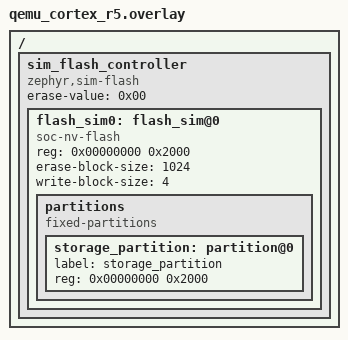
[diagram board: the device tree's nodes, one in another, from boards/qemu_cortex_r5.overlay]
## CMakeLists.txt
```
# Copyright (c) 2023 Intel Corporation.
# SPDX-License-Identifier: Apache-2.0

cmake_minimum_required(VERSION 3.20.0)
find_package(Zephyr REQUIRED HINTS $ENV{ZEPHYR_BASE})
project(llext_simple_test)

target_sources(app PRIVATE
  src/test_llext_simple.c
)

target_include_directories(app PRIVATE
  ${ZEPHYR_BASE}/include
  ${ZEPHYR_BASE}/kernel/include
  ${ZEPHYR_BASE}/arch/${ARCH}/include
)

set(ext_names
	hello_world
	logging
	relative_jump
	object
	syscalls
	threads_kernel_objects
	export_dependent
	export_dependency
)

if(CONFIG_ARM)
  if(NOT CONFIG_CPU_CORTEX_M0 AND NOT CONFIG_CPU_CORTEX_M0PLUS AND NOT CONFIG_CPU_CORTEX_M1)
    list(APPEND ext_names movwmovt)
  endif()
endif()

if (CONFIG_LLEXT_TYPE_ELF_RELOCATABLE AND NOT CONFIG_ARM)
    list(APPEND ext_names pre_located)
endif()

if (CONFIG_LLEXT_STORAGE_WRITABLE)
    list(APPEND ext_names find_section detached_fn)
endif()

if (NOT CONFIG_LLEXT_TYPE_ELF_SHAREDLIB)
    # ELF shared libraries do not support init sections
    list(APPEND ext_names init_fini)
endif()

# generate extension targets foreach extension given by 'ext_names'
foreach(ext_name ${ext_names})
  set(ext_src ${PROJECT_SOURCE_DIR}/src/${ext_name}_ext.c)
  set(ext_bin ${ZEPHYR_BINARY_DIR}/${ext_name}.llext)
  set(ext_inc ${ZEPHYR_BINARY_DIR}/include/generated/${ext_name}.inc)
  add_llext_target(${ext_name}_ext
    OUTPUT  ${ext_bin}
    SOURCES ${ext_src}
  )
  generate_inc_file_for_target(app ${ext_bin} ${ext_inc})
endforeach()

if(NOT CONFIG_LLEXT_TYPE_ELF_OBJECT)
  add_llext_target(multi_file_ext
    OUTPUT  ${ZEPHYR_BINARY_DIR}/multi_file.llext
    SOURCES ${PROJECT_SOURCE_DIR}/src/multi_file_ext1.c ${PROJECT_SOURCE_DIR}/src/multi_file_ext2.c
  )
  generate_inc_file_for_target(app ${ZEPHYR_BINARY_DIR}/multi_file.llext
    ${ZEPHYR_BINARY_DIR}/include/generated/multi_file.inc
  )
endif()

if (CONFIG_LLEXT_TYPE_ELF_RELOCATABLE AND NOT CONFIG_ARM AND NOT CONFIG_RISCV)
  # Manually fix the pre_located extension's text address at a multiple of 4
  get_target_property(pre_located_target pre_located_ext lib_target)
  get_target_property(pre_located_file pre_located_ext pkg_input)
  add_llext_command(
    TARGET pre_located_ext
    POST_BUILD
    COMMAND ${CMAKE_C_COMPILER}
    -Wl,-r -Wl,-Ttext=0xbada110c -nostdlib -nodefaultlibs -nostartfiles
    $<TARGET_OBJECTS:${pre_located_target}> -o ${pre_located_file}
  )
endif()

if(NOT CONFIG_LLEXT_TYPE_ELF_OBJECT AND CONFIG_RISCV AND CONFIG_RISCV_ISA_EXT_C)
  add_llext_target(riscv_edge_case_cb_type_ext
    OUTPUT  ${ZEPHYR_BINARY_DIR}/riscv_edge_case_cb_type_ext.llext
    SOURCES ${PROJECT_SOURCE_DIR}/src/riscv_edge_case_cb_type.c ${PROJECT_SOURCE_DIR}/src/riscv_edge_case_cb_type_trigger.S
  )
  generate_inc_file_for_target(app ${ZEPHYR_BINARY_DIR}/riscv_edge_case_cb_type_ext.llext
    ${ZEPHYR_BINARY_DIR}/include/generated/riscv_edge_case_cb_type.inc
  )
endif()
```

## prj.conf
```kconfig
CONFIG_ZTEST=y
CONFIG_ZTEST_STACK_SIZE=4096
CONFIG_LOG=y
CONFIG_LLEXT=y
CONFIG_LLEXT_HEAP_SIZE=64
CONFIG_LLEXT_EXPORT_DEVICES=y
CONFIG_LLEXT_LOG_LEVEL_DBG=y

CONFIG_APPLICATION_DEFINED_SYSCALL=y

# The bulk of the tests run with MPU/MMU disabled by including additional
# configuration entries from no_mem_protection.conf.
```

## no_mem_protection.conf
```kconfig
# Disable MPU and MMU on all supported arches for the bulk of the tests.
#
# This uses the fact that setting an unknown symbol to 'n' has no effect,
# so it is safe to group different arch-specific settings here.
#
CONFIG_ARM_MPU=n
CONFIG_ARM_AARCH32_MMU=n
CONFIG_RISCV_PMP=n
```

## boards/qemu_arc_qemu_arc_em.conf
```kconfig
CONFIG_FILE_SYSTEM=y
CONFIG_FILE_SYSTEM_LITTLEFS=y
CONFIG_FS_LITTLEFS_FMP_DEV=y
CONFIG_FLASH_MAP=y
CONFIG_FLASH=y
CONFIG_FLASH_SIMULATOR=y
# remove when MPU is enabled
CONFIG_ARC_MPU_ENABLE=n
```

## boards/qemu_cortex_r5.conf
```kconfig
CONFIG_FILE_SYSTEM=y
CONFIG_FILE_SYSTEM_LITTLEFS=y
CONFIG_FS_LITTLEFS_FMP_DEV=y
CONFIG_FLASH_MAP=y
CONFIG_FLASH=y
CONFIG_FLASH_SIMULATOR=y
```

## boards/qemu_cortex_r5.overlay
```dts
/ {
	sim_flash_controller: sim_flash_controller {
		compatible = "zephyr,sim-flash";

		#address-cells = <1>;
		#size-cells = <1>;
		erase-value = <0x00>;

		flash_sim0: flash_sim@0 {
			compatible = "soc-nv-flash";
			reg = <0x00000000 0x2000>;

			erase-block-size = <1024>;
			write-block-size = <4>;

			partitions {
				compatible = "fixed-partitions";
				#address-cells = <1>;
				#size-cells = <1>;

				storage_partition: partition@0 {
					label = "storage_partition";
					reg = <0x00000000 0x2000>;
				};
			};
		};
	};
};
```

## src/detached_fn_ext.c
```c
/*
 * Copyright (c) 2024 Intel Corporation.
 *
 * SPDX-License-Identifier: Apache-2.0
 */

#include <stdint.h>
#include <zephyr/llext/symbol.h>
#include <zephyr/sys/printk.h>
#include <zephyr/ztest_assert.h>

__section(".detach") void detached_entry(void)
{
	static unsigned int cnt;

	zassert_true(cnt < 2);
	printk("call #%u\n", cnt++);
}
EXPORT_SYMBOL(detached_entry);

void test_entry(void)
{
	detached_entry();
}
EXPORT_SYMBOL(test_entry);
```

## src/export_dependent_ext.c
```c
/*
 * Copyright (c) 2024 Intel Corporation.
 *
 * SPDX-License-Identifier: Apache-2.0
 */

/* Test importing symbols, exported by other LLEXTs */

#include <zephyr/ztest.h>
#include <zephyr/llext/symbol.h>
#include <zephyr/sys/util.h>

extern long test_dependency(int a, int b);

void test_entry(void)
{
	unsigned long half_ptr_bits = sizeof(uintptr_t) * 8 / 2;
	unsigned long mask = BIT(half_ptr_bits) - 1;
	int a = mask & (uintptr_t)test_entry;
	int b = mask & ((uintptr_t)test_entry >> half_ptr_bits);

	zassert_equal(test_dependency(a, b), (long)a * b);
}
EXPORT_SYMBOL(test_entry);
```

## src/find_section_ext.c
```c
/*
 * Copyright (c) 2024 Arduino SA
 *
 * SPDX-License-Identifier: Apache-2.0
 */

/* This very basic extension only contains a global variable "number", which is
 * expected to be mapped at offset 0 in the .data section. This can be used in
 * CONFIG_LLEXT_STORAGE_WRITABLE-enabled builds to verify that the variable
 * address, as calculated by the llext loader, matches the start of the .data
 * section in the ELF buffer as returned by llext_find_section.
 *
 * If only this test fails, the llext_find_section API is likely broken.
 */

#include <zephyr/llext/symbol.h>

int number = 42;

void test_entry(void)
{
	/* unused */
}

LL_EXTENSION_SYMBOL(number);
```

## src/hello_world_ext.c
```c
/*
 * Copyright (c) 2023 Intel Corporation.
 *
 * SPDX-License-Identifier: Apache-2.0
 */

/*
 * This very simple hello world C code can be used as a test case for building
 * probably the simplest loadable extension. It requires a single symbol be
 * linked, section relocation support, and the ability to export and call out to
 * a function.
 */

#include <stdint.h>
#include <zephyr/llext/symbol.h>
#include <zephyr/sys/printk.h>
#include <zephyr/ztest_assert.h>

static const uint32_t number = 42;

void test_entry(void)
{
	printk("hello world\n");
	printk("A number is %u\n", number);
	zassert_equal(number, 42);
}
EXPORT_SYMBOL(test_entry);
```

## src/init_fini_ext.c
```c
/*
 * Copyright (c) 2024 Arduino SA
 *
 * SPDX-License-Identifier: Apache-2.0
 */

/*
 * This test checks for proper support of ELF init arrays. This processing is
 * performed by llext_bootstrap(), which gets the array of function pointers
 * from LLEXT via the llext_get_fn_table() syscall.
 *
 * Each function in this test shifts the number left by 4 bits and sets the
 * lower 4 bits to a specific value. The proper init sequence (preinit_fn_1,
 * preinit_fn_2, init_fn) would leave number set to 0x123; the termination
 * function will further shift the number to 0x1234. If a different result is
 * detected, then either not all routines were executed, or their order was not
 * correct.
 */

#include <stdint.h>
#include <zephyr/llext/symbol.h>
#include <zephyr/toolchain.h>
#include <zephyr/sys/printk.h>
#include <zephyr/ztest_assert.h>

static int number;
EXPORT_SYMBOL(number);

static void preinit_fn_1(void)
{
	number = 1;
}

static void preinit_fn_2(void)
{
	number <<= 4;
	number |= 2;
}

static void init_fn(void)
{
	number <<= 4;
	number |= 3;
}

static void fini_fn(void)
{
	number <<= 4;
	number |= 4;
}

static const void *const preinit_fn_ptrs[] __used Z_GENERIC_SECTION(".preinit_array") = {
	preinit_fn_1,
	preinit_fn_2
};
static const void *const init_fn_ptrs[] __used Z_GENERIC_SECTION(".init_array") = {
	init_fn
};
static const void *const fini_fn_ptrs[] __used Z_GENERIC_SECTION(".fini_array") = {
	fini_fn
};

void test_entry(void)
{
	/* fini_fn() is not called yet, so we expect 0x123 here */
	const int expected = (((1 << 4) | 2) << 4) | 3;

	zassert_equal(number, expected, "got 0x%x instead of 0x%x during test",
		      number, expected);
}
EXPORT_SYMBOL(test_entry);
```

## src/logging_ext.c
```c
/*
 * Copyright (c) 2023 Intel Corporation.
 *
 * SPDX-License-Identifier: Apache-2.0
 */

/*
 * This very simple hello world C code can be used as a test case for building
 * probably the simplest loadable extension. It requires a single symbol be
 * linked, section relocation support, and the ability to export and call out to
 * a function.
 */

#include <stdint.h>
#include <zephyr/llext/symbol.h>
#include <zephyr/logging/log.h>
LOG_MODULE_REGISTER(logging_ext);

static const uint32_t number = 42;

void test_entry(void)
{
	LOG_INF("hello world");
	LOG_INF("A number is %" PRIu32, number);
}
LL_EXTENSION_SYMBOL(test_entry);
```

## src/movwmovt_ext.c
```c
/*
 * Copyright (c) 2024 Schneider Electric.
 *
 * SPDX-License-Identifier: Apache-2.0
 */

/*
 * This test is designed to test MOV.W and MOV.T instructions on ARM architectures.
 * (except Cortex-M0, M0+ and M1, that don't support them)
 */

#include <stdint.h>
#include <zephyr/llext/symbol.h>
#include <zephyr/sys/printk.h>
#include <zephyr/ztest_assert.h>

static int test_var;

static __used void test_func(void)
{
	printk("%s\n", __func__);
	test_var = 1;
}

void test_entry(void)
{
	test_var = 0;

	printk("test movwmovt\n");
	__asm volatile ("movw r0, #:lower16:test_func");
	__asm volatile ("movt r0, #:upper16:test_func");
	__asm volatile ("blx r0");
	zassert_equal(test_var, 1, "mov.w and mov.t test failed");
}
LL_EXTENSION_SYMBOL(test_entry);
```

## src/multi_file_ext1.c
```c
/*
 * Copyright (c) 2024 Intel Corporation.
 *
 * SPDX-License-Identifier: Apache-2.0
 */

/*
 * This code demonstrates multi-file object and function linking support.
 */

#include <stdint.h>
#include <zephyr/llext/symbol.h>
#include <zephyr/kernel.h>
#include <zephyr/ztest_assert.h>

/* Test non-static global object relocation */
int number = 0x42;
extern int ext_number;
int ext_sum_fn(int arg);

int run_id = 41;

void test_entry(void)
{
	switch (run_id) {
	case 41:
		/* initial run: test variable initialization */
		break;
	case 42:
		/* user-mode run: reinit number */
		number = 0x42;
		break;
	default:
		/* possible llext loader issue */
		zassert_unreachable("unexpected run_id %d", run_id);
		return;
	}

	printk("initial: local %d plus external %d equals %d\n",
	       number, ext_number, ext_sum_fn(ext_number));
	zassert_equal(number, 0x42);
	zassert_equal(ext_number, 0x18);
	number ^= ext_number;
	ext_number ^= number;
	number ^= ext_number;
	zassert_equal(number, 0x18);
	zassert_equal(ext_number, 0x42);
	printk("updated: local %d plus external %d equals %d\n",
	       number, ext_number, ext_sum_fn(ext_number));

	run_id += 1;
}
LL_EXTENSION_SYMBOL(test_entry);
```

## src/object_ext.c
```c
/*
 * Copyright (c) 2024 Intel Corporation.
 *
 * SPDX-License-Identifier: Apache-2.0
 */

/*
 * This code demonstrates object relocation support.
 */

#include <stdint.h>
#include <zephyr/llext/symbol.h>
#include <zephyr/kernel.h>
#include <zephyr/ztest_assert.h>

/* Test non-static global object relocation */
int number = 42;
const char *string = "hello";

int run_id = 41;

void test_entry(void)
{
	switch (run_id) {
	case 41:
		/* initial run: test variable initialization */
		break;
	case 42:
		/* user-mode run: reinit number */
		number = 42;
		break;
	default:
		/* possible llext loader issue */
		zassert_unreachable("unexpected run_id %d", run_id);
		return;
	}

	printk("number: %d\n", number);
	zassert_equal(number, 42);
	number = 0;
	printk("number, updated: %d\n", number);
	zassert_equal(number, 0);
	printk("string: %s\n", string);
	zassert_ok(strcmp(string, "hello"));

	run_id += 1;
}
LL_EXTENSION_SYMBOL(test_entry);
```

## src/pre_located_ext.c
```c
/*
 * Copyright (c) 2024 Arduino SA.
 *
 * SPDX-License-Identifier: Apache-2.0
 */

/*
 * This file contains a simple test extension that defines an entry point
 * in the .text section. The entry point is never called, but the symbol
 * address is fixed via a linker call and then checked by the test.
 */

#include <zephyr/llext/symbol.h>

void test_entry(void)
{
	/* This function is never called */
}
EXPORT_SYMBOL(test_entry);
```

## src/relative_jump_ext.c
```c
/*
 * Copyright (c) 2024 Trackunit Corporation
 *
 * SPDX-License-Identifier: Apache-2.0
 */

/*
 * This test is designed to test linking global symbols, which for some architectures
 * like ARM generate relative jumps rather than jumping to absolute addresses. Multiple
 * global functions are created to hopefully generate both positive and negative relative
 * jumps.
 */

#include <stdint.h>
#include <zephyr/llext/symbol.h>
#include <zephyr/sys/printk.h>
#include <zephyr/ztest_assert.h>

static int test_var;

void test_relative_jump_1(void);
void test_relative_jump_2(void);
void test_relative_jump_3(void);
void test_relative_jump_4(void);
void test_relative_jump_5(void);

void test_relative_jump_5(void)
{
	printk("relative jump 5\n");
	test_var = 1;
}

void test_relative_jump_4(void)
{
	printk("relative jump 4\n");
	test_relative_jump_5();
}

void test_relative_jump_2(void)
{
	printk("relative jump 2\n");
	test_relative_jump_3();
}

void test_relative_jump_1(void)
{
	printk("relative jump 1\n");
	test_relative_jump_2();
}

void test_relative_jump_3(void)
{
	printk("relative jump 3\n");
	test_relative_jump_4();
}

void test_entry(void)
{
	printk("enter\n");
	test_var = 0;
	test_relative_jump_1();
	printk("exit\n");
	zassert_equal(test_var, 1, "relative jump test failed");
}
LL_EXTENSION_SYMBOL(test_entry);
```

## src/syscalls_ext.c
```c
/*
 * Copyright (c) 2024 Intel Corporation.
 *
 * SPDX-License-Identifier: Apache-2.0
 */

/*
 * This code demonstrates syscall support.
 */

#include <zephyr/llext/symbol.h>
#include <zephyr/sys/printk.h>
#include <zephyr/ztest_assert.h>

#include "syscalls_ext.h"

void test_entry(void)
{
	int input = 41;
	int output = ext_syscall_ok(input);

	printk("Input: %d Expected output: %d Actual output: %d\n",
	       input, input + 1, output);
	zassert_equal(output, input + 1);
}
LL_EXTENSION_SYMBOL(test_entry);
```
